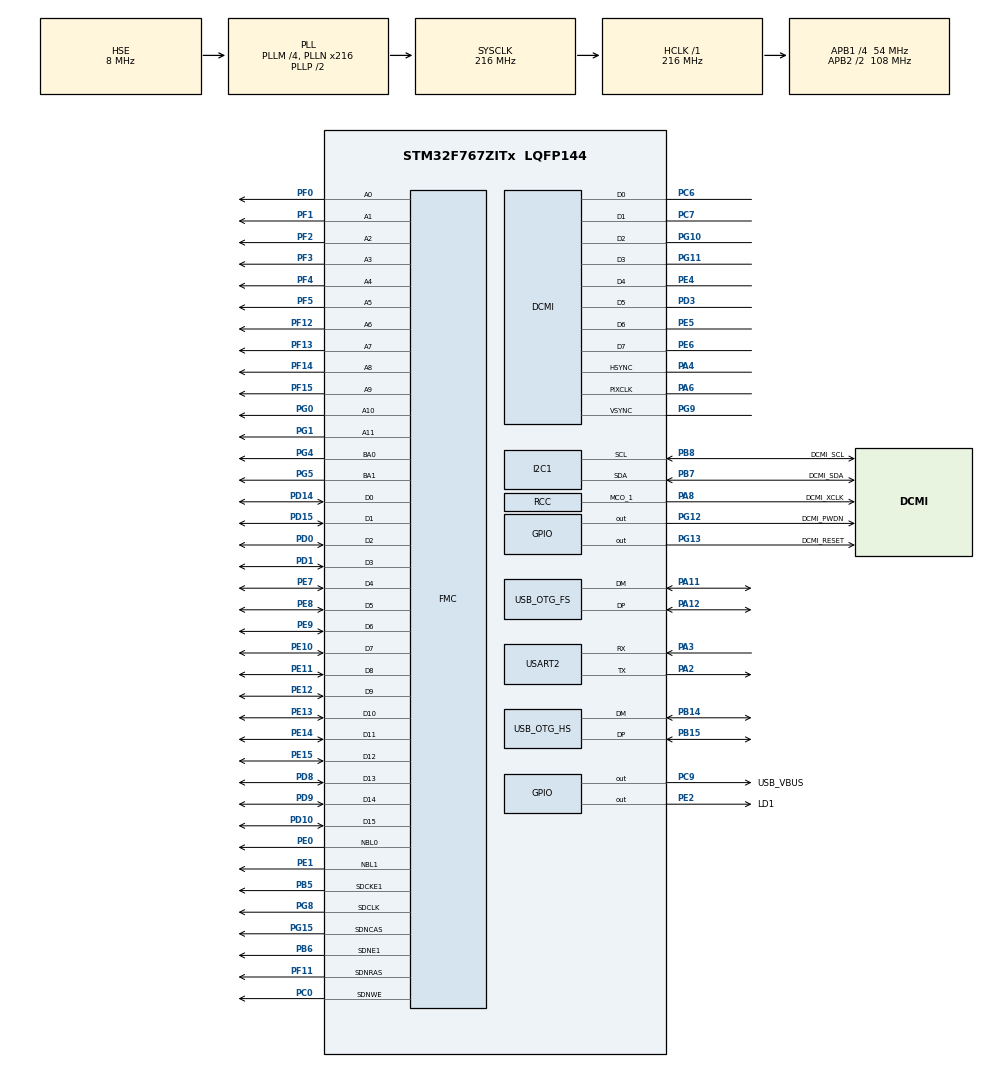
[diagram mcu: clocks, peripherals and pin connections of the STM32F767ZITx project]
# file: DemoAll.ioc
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CORTEX_M7.CPU_DCache=Enabled
CORTEX_M7.CPU_ICache=Enabled
CORTEX_M7.PREFETCH_ENABLE=1
CRC.InputDataFormat=CRC_INPUTDATA_FORMAT_HALFWORDS
DCMI.HSPolarity=DCMI_HSPOLARITY_LOW
DCMI.PCKPolarity=DCMI_PCKPOLARITY_RISING
DCMI.VSPolarity=DCMI_VSPOLARITY_HIGH
Dma.DCMI.0.Direction=DMA_PERIPH_TO_MEMORY
Dma.DCMI.0.FIFOMode=DMA_FIFOMODE_ENABLE
Dma.DCMI.0.FIFOThreshold=DMA_FIFO_THRESHOLD_FULL
Dma.DCMI.0.Instance=DMA2_Stream1
Dma.DCMI.0.MemBurst=DMA_MBURST_SINGLE
Dma.DCMI.0.MemDataAlignment=DMA_MDATAALIGN_WORD
Dma.DCMI.0.MemInc=DMA_MINC_ENABLE
Dma.DCMI.0.Mode=DMA_CIRCULAR
Dma.DCMI.0.PeriphBurst=DMA_PBURST_SINGLE
Dma.DCMI.0.PeriphDataAlignment=DMA_PDATAALIGN_WORD
Dma.DCMI.0.PeriphInc=DMA_PINC_DISABLE
Dma.DCMI.0.Priority=DMA_PRIORITY_HIGH
Dma.Request0=DCMI
FATFS._CODE_PAGE=850
FATFS._LFN_UNICODE=0
FATFS._MAX_LFN=128
FATFS._USE_LFN=1
FMC.CASLatency1=FMC_SDRAM_CAS_LATENCY_2
FMC.ExitSelfRefreshDelay1=8
FMC.LoadToActiveDelay1=2
FMC.RCDDelay1=3
FMC.RPDelay1=2
FMC.ReadBurst1=FMC_SDRAM_RBURST_DISABLE
FMC.RowCycleDelay1=7
FMC.SDClockPeriod1=FMC_SDRAM_CLOCK_PERIOD_2
FMC.SelfRefreshTime1=5
FMC.WriteRecoveryTime1=2
I2C1.Timing=0x20404768
JPEG.JPEG_RGB_FORMAT=JPEG_RGB565
Mcu.Family=STM32F7
Mcu.Name=STM32F767ZITx
Mcu.Package=LQFP144
NVIC.DCMI_IRQn=true\:1\:0\:true\:false\:true\:true\:true
NVIC.DMA2_Stream1_IRQn=true\:0\:0\:false\:false\:true\:false\:true
NVIC.FMC_IRQn=true\:0\:0\:false\:false\:true\:true\:true
NVIC.JPEG_IRQn=true\:0\:0\:false\:false\:true\:false\:true
NVIC.OTG_FS_IRQn=true\:0\:0\:false\:false\:true\:false\:true
NVIC.OTG_HS_IRQn=true\:0\:0\:false\:false\:true\:false\:true
NVIC.PriorityGroup=NVIC_PRIORITYGROUP_4
NVIC.RCC_IRQn=true\:0\:0\:false\:false\:true\:true\:false
PA11.Mode=Host_Only
PA11.Signal=USB_OTG_FS_DM
PA12.Mode=Host_Only
PA12.Signal=USB_OTG_FS_DP
PA13.Mode=Serial_Wire
PA13.Signal=SYS_JTMS-SWDIO
PA14.Mode=Serial_Wire
PA14.Signal=SYS_JTCK-SWCLK
PA2.Mode=Asynchronous
PA2.Signal=USART2_TX
PA3.Mode=Asynchronous
PA3.Signal=USART2_RX
PA4.Mode=Slave_8_bits_External_Synchro
PA4.Signal=DCMI_HSYNC
PA6.Mode=Slave_8_bits_External_Synchro
PA6.Signal=DCMI_PIXCLK
PA8.GPIO_Label=DCMI_XCLK
PA8.Mode=Clock-out-1
PA8.Signal=RCC_MCO_1
PB14.Mode=Device_Only_FS
PB14.Signal=USB_OTG_HS_DM
PB15.GPIO_PuPd=GPIO_NOPULL
PB15.Mode=Device_Only_FS
PB15.Signal=USB_OTG_HS_DP
PB5.Mode=SdramChipSelect2_1
PB5.Signal=FMC_SDCKE1
PB6.Mode=SdramChipSelect2_1
PB6.Signal=FMC_SDNE1
PB7.GPIO_Label=DCMI_SDA
PB7.Mode=I2C
PB7.Signal=I2C1_SDA
PB8.GPIO_Label=DCMI_SCL
PB8.Mode=I2C
PB8.Signal=I2C1_SCL
PC0.Signal=FMC_SDNWE
PC6.Mode=Slave_8_bits_External_Synchro
PC6.Signal=DCMI_D0
PC7.Mode=Slave_8_bits_External_Synchro
PC7.Signal=DCMI_D1
PC9.GPIO_Label=USB_VBUS
PC9.Signal=GPIO_Output
PD0.Signal=FMC_D2_DA2
PD1.Signal=FMC_D3_DA3
PD10.Signal=FMC_D15_DA15
PD14.Signal=FMC_D0_DA0
PD15.Signal=FMC_D1_DA1
PD3.Mode=Slave_8_bits_External_Synchro
PD3.Signal=DCMI_D5
PD8.Signal=FMC_D13_DA13
PD9.Signal=FMC_D14_DA14
PE0.Signal=FMC_NBL0
PE1.Signal=FMC_NBL1
PE10.Signal=FMC_D7_DA7
PE11.Signal=FMC_D8_DA8
PE12.Signal=FMC_D9_DA9
PE13.Signal=FMC_D10_DA10
PE14.Signal=FMC_D11_DA11
PE15.Signal=FMC_D12_DA12
PE2.GPIO_Label=LD1
PE2.Signal=GPIO_Output
PE4.Mode=Slave_8_bits_External_Synchro
PE4.Signal=DCMI_D4
PE5.Mode=Slave_8_bits_External_Synchro
PE5.Signal=DCMI_D6
PE6.Mode=Slave_8_bits_External_Synchro
PE6.Signal=DCMI_D7
PE7.Signal=FMC_D4_DA4
PE8.Signal=FMC_D5_DA5
PE9.Signal=FMC_D6_DA6
PF0.Signal=FMC_A0
PF1.Signal=FMC_A1
PF11.Signal=FMC_SDNRAS
PF12.Signal=FMC_A6
PF13.Signal=FMC_A7
PF14.Signal=FMC_A8
PF15.Signal=FMC_A9
PF2.Signal=FMC_A2
PF3.Signal=FMC_A3
PF4.Signal=FMC_A4
PF5.Signal=FMC_A5
PG0.Signal=FMC_A10
PG1.Signal=FMC_A11
PG10.Mode=Slave_8_bits_External_Synchro
PG10.Signal=DCMI_D2
PG11.Mode=Slave_8_bits_External_Synchro
PG11.Signal=DCMI_D3
PG12.GPIO_Label=DCMI_PWDN
PG12.Signal=GPIO_Output
PG13.GPIO_Label=DCMI_RESET
PG13.Signal=GPIO_Output
PG15.Signal=FMC_SDNCAS
PG4.Signal=FMC_A14_BA0
PG5.Signal=FMC_A15_BA1
PG8.Signal=FMC_SDCLK
PG9.Mode=Slave_8_bits_External_Synchro
PG9.Signal=DCMI_VSYNC
PH0/OSC_IN.Mode=HSE-External-Oscillator
PH0/OSC_IN.Signal=RCC_OSC_IN
PH1/OSC_OUT.Mode=HSE-External-Oscillator
PH1/OSC_OUT.Signal=RCC_OSC_OUT
ProjectManager.HeapSize=0x10000
ProjectManager.StackSize=0x12000
ProjectManager.TargetToolchain=TrueSTUDIO
RCC.AHBFreq_Value=216000000
RCC.APB1CLKDivider=RCC_HCLK_DIV4
RCC.APB1Freq_Value=54000000
RCC.APB1TimFreq_Value=108000000
RCC.APB2CLKDivider=RCC_HCLK_DIV2
RCC.APB2Freq_Value=108000000
RCC.APB2TimFreq_Value=216000000
RCC.CortexFreq_Value=216000000
RCC.HCLKFreq_Value=216000000
RCC.HSE_VALUE=8000000
RCC.HSI_VALUE=16000000
RCC.LSE_VALUE=32768
RCC.PLLM=4
RCC.PLLN=216
RCC.PLLQ=9
RCC.RCC_MCO1Source=RCC_MCO1SOURCE_HSE
RCC.SDMMCClockSelection=RCC_SDMMC1CLKSOURCE_CLK48
RCC.SYSCLKFreq_VALUE=216000000
RCC.SYSCLKSource=RCC_SYSCLKSOURCE_PLLCLK
RCC.USBFreq_Value=48000000
RCC.VCOOutputFreq_Value=432000000
SH.FMC_A0.0=FMC_A0,12b-sda1
SH.FMC_A1.0=FMC_A1,12b-sda1
SH.FMC_A10.0=FMC_A10,12b-sda1
SH.FMC_A11.0=FMC_A11,12b-sda1
SH.FMC_A14_BA0.0=FMC_BA0,FourSdramBanks1
SH.FMC_A15_BA1.0=FMC_BA1,FourSdramBanks1
SH.FMC_A2.0=FMC_A2,12b-sda1
SH.FMC_A3.0=FMC_A3,12b-sda1
SH.FMC_A4.0=FMC_A4,12b-sda1
SH.FMC_A5.0=FMC_A5,12b-sda1
SH.FMC_A6.0=FMC_A6,12b-sda1
SH.FMC_A7.0=FMC_A7,12b-sda1
SH.FMC_A8.0=FMC_A8,12b-sda1
SH.FMC_A9.0=FMC_A9,12b-sda1
SH.FMC_D0_DA0.0=FMC_D0,sd-16b-d1
SH.FMC_D10_DA10.0=FMC_D10,sd-16b-d1
SH.FMC_D11_DA11.0=FMC_D11,sd-16b-d1
SH.FMC_D12_DA12.0=FMC_D12,sd-16b-d1
SH.FMC_D13_DA13.0=FMC_D13,sd-16b-d1
SH.FMC_D14_DA14.0=FMC_D14,sd-16b-d1
SH.FMC_D15_DA15.0=FMC_D15,sd-16b-d1
SH.FMC_D1_DA1.0=FMC_D1,sd-16b-d1
SH.FMC_D2_DA2.0=FMC_D2,sd-16b-d1
SH.FMC_D3_DA3.0=FMC_D3,sd-16b-d1
SH.FMC_D4_DA4.0=FMC_D4,sd-16b-d1
SH.FMC_D5_DA5.0=FMC_D5,sd-16b-d1
SH.FMC_D6_DA6.0=FMC_D6,sd-16b-d1
SH.FMC_D7_DA7.0=FMC_D7,sd-16b-d1
SH.FMC_D8_DA8.0=FMC_D8,sd-16b-d1
SH.FMC_D9_DA9.0=FMC_D9,sd-16b-d1
SH.FMC_NBL0.0=FMC_NBL0,Sd2ByteEnable1
SH.FMC_NBL1.0=FMC_NBL1,Sd2ByteEnable1
SH.FMC_SDCLK.0=FMC_SDCLK,12b-sda1
SH.FMC_SDNCAS.0=FMC_SDNCAS,12b-sda1
SH.FMC_SDNRAS.0=FMC_SDNRAS,12b-sda1
SH.FMC_SDNWE.0=FMC_SDNWE,12b-sda1
USART2.VirtualMode-Asynchronous=VM_ASYNC
USART2.WordLength=WORDLENGTH_8B
USB_DEVICE.APP_RX_DATA_SIZE-CDC_HS=128
USB_DEVICE.APP_TX_DATA_SIZE-CDC_HS=512
USB_DEVICE.CLASS_NAME_HS=CDC
USB_DEVICE.USBD_MAX_NUM_CONFIGURATION-CDC_HS=1
USB_DEVICE.USBD_MAX_NUM_INTERFACES-CDC_HS=1
USB_DEVICE.USBD_SELF_POWERED-CDC_HS=1
USB_DEVICE.VID-CDC_HS=11550
USB_DEVICE.VirtualMode-CDC_HS=Cdc
USB_DEVICE.VirtualModeHS=Cdc_HS
USB_HOST.USBH_HandleTypeDef-MSC_FS=hUsbHostFS
USB_HOST.VirtualModeFS=Msc
USB_OTG_FS.Sof_enable=DISABLE
USB_OTG_FS.VirtualMode=Host_Only
USB_OTG_FS.phy_itface=HCD_PHY_EMBEDDED
USB_OTG_HS.Sof_enable-Device_Only_FS=DISABLE
USB_OTG_HS.VirtualMode-Device_Only_FS=Device_Only_FS
USB_OTG_HS.dma_enable-Device_Only_FS=ENABLE
VP_CRC_VS_CRC.Mode=CRC_Activate
VP_FATFS_VS_USB.Mode=USB
VP_JPEG_VS_JPEG.Mode=JPEG_Activate
VP_USB_DEVICE_VS_USB_DEVICE_CDC_HS.Mode=CDC_HS
VP_USB_HOST_VS_USB_HOST_MSC_FS.Mode=MSC_FS
board=Demo1

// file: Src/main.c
/* USER CODE BEGIN Header */
/**
 ******************************************************************************
 * @file           : main.c
 * @brief          : Main program body
 ******************************************************************************
 * This notice applies to any and all portions of this file
 * that are not between comment pairs USER CODE BEGIN and
 * USER CODE END. Other portions of this file, whether
 * inserted by the user or by software development tools
 * are owned by their respective copyright owners.
 *
 * Copyright (c) 2018 STMicroelectronics International N.V.
 * All rights reserved.
 *
 * Redistribution and use in source and binary forms, with or without
 * modification, are permitted, provided that the following conditions are met:
 *
 * 1. Redistribution of source code must retain the above copyright notice,
 *    this list of conditions and the following disclaimer.
 * 2. Redistributions in binary form must reproduce the above copyright notice,
 *    this list of conditions and the following disclaimer in the documentation
 *    and/or other materials provided with the distribution.
 * 3. Neither the name of STMicroelectronics nor the names of other
 *    contributors to this software may be used to endorse or promote products
 *    derived from this software without specific written permission.
 * 4. This software, including modifications and/or derivative works of this
 *    software, must execute solely and exclusively on microcontroller or
 *    microprocessor devices manufactured by or for STMicroelectronics.
 * 5. Redistribution and use of this software other than as permitted under
 *    this license is void and will automatically terminate your rights under
 *    this license.
 *
 * THIS SOFTWARE IS PROVIDED BY STMICROELECTRONICS AND CONTRIBUTORS "AS IS"
 * AND ANY EXPRESS, IMPLIED OR STATUTORY WARRANTIES, INCLUDING, BUT NOT
 * LIMITED TO, THE IMPLIED WARRANTIES OF MERCHANTABILITY, FITNESS FOR A
 * PARTICULAR PURPOSE AND NON-INFRINGEMENT OF THIRD PARTY INTELLECTUAL PROPERTY
 * RIGHTS ARE DISCLAIMED TO THE FULLEST EXTENT PERMITTED BY LAW. IN NO EVENT
 * SHALL STMICROELECTRONICS OR CONTRIBUTORS BE LIABLE FOR ANY DIRECT, INDIRECT,
 * INCIDENTAL, SPECIAL, EXEMPLARY, OR CONSEQUENTIAL DAMAGES (INCLUDING, BUT NOT
 * LIMITED TO, PROCUREMENT OF SUBSTITUTE GOODS OR SERVICES; LOSS OF USE, DATA,
 * OR PROFITS; OR BUSINESS INTERRUPTION) HOWEVER CAUSED AND ON ANY THEORY OF
 * LIABILITY, WHETHER IN CONTRACT, STRICT LIABILITY, OR TORT (INCLUDING
 * NEGLIGENCE OR OTHERWISE) ARISING IN ANY WAY OUT OF THE USE OF THIS SOFTWARE,
 * EVEN IF ADVISED OF THE POSSIBILITY OF SUCH DAMAGE.
 *
 ******************************************************************************
 */
/* USER CODE END Header */

#include "main.h"
#include "crc.h"
#include "dcmi.h"
#include "dma.h"
#include "fatfs.h"
#include "i2c.h"
#include "jpeg.h"
#include "usart.h"
#include "usb_device.h"
#include "usb_host.h"
#include "gpio.h"
#include "fmc.h"

/* USER CODE BEGIN Includes */
#include <stdlib.h>
#include "bsp.h"
/* USER CODE END Includes */

/* USER CODE BEGIN PV */
/* Private variables ---------------------------------------------------------*/

/* USER CODE END PV */

void SystemClock_Config(void);
void MX_USB_HOST_Process(void);

/* USER CODE BEGIN PFP */
/* Private function prototypes -----------------------------------------------*/

/* USER CODE END PFP */

/* USER CODE BEGIN 0 */
//SDRAM_DATA uint16_t SdramTestBuf[1024];
//void Sdram_Test(void)
//{
//	uint8_t txbuf[64];
//	for (int i = 0; i < 1024; i++)
//	{
//		SdramTestBuf[i] = i + 1;
//	}
//	for (int i = 0; i < 1024; i++)
//	{
//		sprintf(txbuf, "Buf[%04d]0x%p=%d ", i, &SdramTestBuf[i], SdramTestBuf[i]);
//		BSP_USBCDC_SendTxtTest((char*) txbuf);
//		if (i % 16 == 0)
//		{
//			BSP_USBCDC_SendTxtTest("\r\n");
//			HAL_Delay(10);
//		}
//	}
//}
/* USER CODE END 0 */

int main(void)
{

  /* Enable I-Cache---------------------------------------------------------*/
  SCB_EnableICache();

  /* Enable D-Cache---------------------------------------------------------*/
  SCB_EnableDCache();

  /* MCU Configuration--------------------------------------------------------*/

  /* Reset of all peripherals, Initializes the Flash interface and the Systick. */
  HAL_Init();

  /* Configure the system clock */
  SystemClock_Config();

  /* Initialize all configured peripherals */
  MX_GPIO_Init();
  MX_DMA_Init();
  MX_FMC_Init();
  MX_USB_HOST_Init();
  MX_CRC_Init();
  MX_DCMI_Init();
  MX_USB_DEVICE_Init();
  MX_FATFS_Init();
  MX_I2C1_Init();
  MX_JPEG_Init();
  MX_USART2_UART_Init();
  /* USER CODE BEGIN 2 */
	BSP_SDRAM_Configuration();
	BSP_OVCAM_Configuration();

  /* USER CODE END 2 */

  /* Infinite loop */
  /* USER CODE BEGIN WHILE */
	BSP_OVCAM_StartSnapshot();

	while (1)
	{

    /* USER CODE END WHILE */
    MX_USB_HOST_Process();

    /* USER CODE BEGIN 3 */
		//BSP_USBCDC_SendTxtTest("hello world\r\n");
		//HAL_GPIO_TogglePin(LD1_GPIO_Port, LD1_Pin) ;
		//HAL_Delay(500) ;
		//Sdram_Test();
		//HAL_Delay(2000) ;
	}
  /* USER CODE END 3 */
}

void SystemClock_Config(void)
{
  RCC_OscInitTypeDef RCC_OscInitStruct = {0};
  RCC_ClkInitTypeDef RCC_ClkInitStruct = {0};
  RCC_PeriphCLKInitTypeDef PeriphClkInitStruct = {0};

  /** Configure the main internal regulator output voltage
  */
  __HAL_RCC_PWR_CLK_ENABLE();
  __HAL_PWR_VOLTAGESCALING_CONFIG(PWR_REGULATOR_VOLTAGE_SCALE1);
  /** Initializes the CPU, AHB and APB busses clocks
  */
  RCC_OscInitStruct.OscillatorType = RCC_OSCILLATORTYPE_HSE;
  RCC_OscInitStruct.HSEState = RCC_HSE_ON;
  RCC_OscInitStruct.PLL.PLLState = RCC_PLL_ON;
  RCC_OscInitStruct.PLL.PLLSource = RCC_PLLSOURCE_HSE;
  RCC_OscInitStruct.PLL.PLLM = 4;
  RCC_OscInitStruct.PLL.PLLN = 216;
  RCC_OscInitStruct.PLL.PLLP = RCC_PLLP_DIV2;
  RCC_OscInitStruct.PLL.PLLQ = 9;
  if (HAL_RCC_OscConfig(&RCC_OscInitStruct) != HAL_OK)
  {
    Error_Handler();
  }
  /** Activate the Over-Drive mode
  */
  if (HAL_PWREx_EnableOverDrive() != HAL_OK)
  {
    Error_Handler();
  }
  /** Initializes the CPU, AHB and APB busses clocks
  */
  RCC_ClkInitStruct.ClockType = RCC_CLOCKTYPE_HCLK|RCC_CLOCKTYPE_SYSCLK
                              |RCC_CLOCKTYPE_PCLK1|RCC_CLOCKTYPE_PCLK2;
  RCC_ClkInitStruct.SYSCLKSource = RCC_SYSCLKSOURCE_PLLCLK;
  RCC_ClkInitStruct.AHBCLKDivider = RCC_SYSCLK_DIV1;
  RCC_ClkInitStruct.APB1CLKDivider = RCC_HCLK_DIV4;
  RCC_ClkInitStruct.APB2CLKDivider = RCC_HCLK_DIV2;

  if (HAL_RCC_ClockConfig(&RCC_ClkInitStruct, FLASH_LATENCY_7) != HAL_OK)
  {
    Error_Handler();
  }
  PeriphClkInitStruct.PeriphClockSelection = RCC_PERIPHCLK_USART2|RCC_PERIPHCLK_I2C1
                              |RCC_PERIPHCLK_CLK48;
  PeriphClkInitStruct.Usart2ClockSelection = RCC_USART2CLKSOURCE_PCLK1;
  PeriphClkInitStruct.I2c1ClockSelection = RCC_I2C1CLKSOURCE_PCLK1;
  PeriphClkInitStruct.Clk48ClockSelection = RCC_CLK48SOURCE_PLL;
  if (HAL_RCCEx_PeriphCLKConfig(&PeriphClkInitStruct) != HAL_OK)
  {
    Error_Handler();
  }
  HAL_RCC_MCOConfig(RCC_MCO1, RCC_MCO1SOURCE_HSE, RCC_MCODIV_1);
}

void Error_Handler(void)
{
	while (1)
	{
	}
}

/************************ (C) COPYRIGHT STMicroelectronics *****END OF FILE****/
